AUTOSAR XML (schema 4-3-0)
package /For_Mira
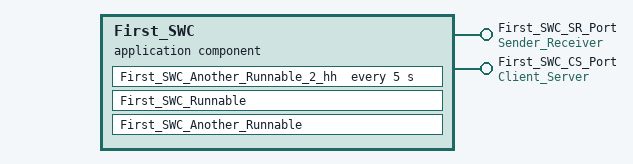
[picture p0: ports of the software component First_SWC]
  application sw component type First_SWC
    provide port First_SWC_SR_Port: nonqueued-sender-com-spec=SR_DataElement, provided-interface=Sender_Receiver
    provide port First_SWC_CS_Port: server-com-spec=CS_Operation, provided-interface=Client_Server
    behavior First_SWC_InternalBehavior
      events:
        init event Init_Event: start-on-event=First_SWC_Runnable
        operation invoked event Operation_Event: start-on-event=First_SWC_Another_Runnable, operation=First_SWC_CS_Port.CS_Operation
        timing event Timing_Event: start-on-event=First_SWC_Another_Runnable_2_hh, period=5
      runnable First_SWC_Runnable: minimum-start-interval=0.05
      runnable First_SWC_Another_Runnable
      runnable First_SWC_Another_Runnable_2_hh
  swc implementation First_SWC_Implementation: behavior=First_SWC_InternalBehavior
